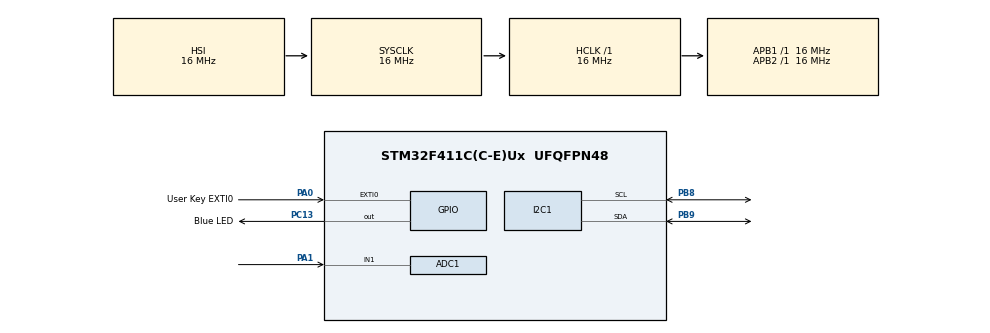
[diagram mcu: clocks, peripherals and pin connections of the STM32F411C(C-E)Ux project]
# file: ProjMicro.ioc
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ADC1.Channel-0\#ChannelRegularConversion=ADC_CHANNEL_1
ADC1.NbrOfConversionFlag=1
ADC1.Rank-0\#ChannelRegularConversion=1
ADC1.SamplingTime-0\#ChannelRegularConversion=ADC_SAMPLETIME_3CYCLES
ADC1.master=1
Mcu.Family=STM32F4
Mcu.Name=STM32F411C(C-E)Ux
Mcu.Package=UFQFPN48
NVIC.ADC_IRQn=true\:0\:0\:false\:false\:true\:true\:true\:true
NVIC.EXTI0_IRQn=true\:0\:0\:false\:false\:true\:true\:true\:true
NVIC.PriorityGroup=NVIC_PRIORITYGROUP_4
NVIC.TIM2_IRQn=true\:0\:0\:false\:false\:true\:true\:true\:true
PA0-WKUP.GPIO_Label=User Key EXTI0
PA0-WKUP.GPIO_PuPd=GPIO_PULLUP
PA0-WKUP.Signal=GPXTI0
PA1.Signal=ADCx_IN1
PA13.Mode=Serial_Wire
PA13.Signal=SYS_JTMS-SWDIO
PA14.Mode=Serial_Wire
PA14.Signal=SYS_JTCK-SWCLK
PB8.Mode=I2C
PB8.Signal=I2C1_SCL
PB9.Mode=I2C
PB9.Signal=I2C1_SDA
PC13-ANTI_TAMP.GPIO_Label=Blue LED
PC13-ANTI_TAMP.PinState=GPIO_PIN_SET
PC13-ANTI_TAMP.Signal=GPIO_Output
PC14-OSC32_IN.Mode=LSE-External-Oscillator
PC14-OSC32_IN.Signal=RCC_OSC32_IN
PC15-OSC32_OUT.Mode=LSE-External-Oscillator
PC15-OSC32_OUT.Signal=RCC_OSC32_OUT
PH0\ -\ OSC_IN.Mode=HSE-External-Oscillator
PH0\ -\ OSC_IN.Signal=RCC_OSC_IN
PH1\ -\ OSC_OUT.Mode=HSE-External-Oscillator
PH1\ -\ OSC_OUT.Signal=RCC_OSC_OUT
ProjectManager.HeapSize=0x200
ProjectManager.StackSize=0x400
ProjectManager.TargetToolchain=CMake
RCC.AHBFreq_Value=16000000
RCC.APB1Freq_Value=16000000
RCC.APB2Freq_Value=16000000
RCC.CortexFreq_Value=16000000
RCC.HSE_VALUE=25000000
RCC.HSI_VALUE=16000000
RCC.SYSCLKFreq_VALUE=16000000
RCC.VCOOutputFreq_Value=192000000
SH.ADCx_IN1.0=ADC1_IN1,IN1
TIM2.AutoReloadPreload=TIM_AUTORELOAD_PRELOAD_ENABLE
TIM2.Period=3999
TIM2.Prescaler=3999
VP_TIM2_VS_ClockSourceINT.Mode=Internal
board=custom

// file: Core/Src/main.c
/* USER CODE BEGIN Header */
/**
  ******************************************************************************
  * @file           : main.c
  * @brief          : Main program body
  ******************************************************************************
  * @attention
  *
  * Copyright (c) 2025 STMicroelectronics.
  * All rights reserved.
  *
  * This software is licensed under terms that can be found in the LICENSE file
  * in the root directory of this software component.
  * If no LICENSE file comes with this software, it is provided AS-IS.
  *
  ******************************************************************************
  */
/* USER CODE END Header */
#include "main.h"

/* USER CODE BEGIN Includes */
#include "stm32f4xx_hal.h"
#include "liquidcrystal_i2c.h"
#include <stdio.h>
#include <stdlib.h>
#include <string.h>

/* USER CODE END Includes */

ADC_HandleTypeDef hadc1;

I2C_HandleTypeDef hi2c1;

TIM_HandleTypeDef htim2;

void SystemClock_Config(void);
static void MX_GPIO_Init(void);
static void MX_I2C1_Init(void);
static void MX_TIM2_Init(void);
static void MX_ADC1_Init(void);

int main(void)
{

  /* MCU Configuration--------------------------------------------------------*/

  /* Reset of all peripherals, Initializes the Flash interface and the Systick. */
  HAL_Init();

  /* Configure the system clock */
  SystemClock_Config();

  /* Initialize all configured peripherals */
  MX_GPIO_Init();
  MX_I2C1_Init();
  MX_TIM2_Init();
  MX_ADC1_Init();
  /* USER CODE BEGIN 2 */
  HAL_TIM_Base_Start_IT(&htim2); //Timer

  HD44780_Init(4);
  HD44780_Clear();
  HD44780_Backlight();

  /* USER CODE END 2 */

  /* Infinite loop */
  while (1)
  {
  HAL_ADC_Start_IT(&hadc1); //ADC
  uint16_t adc1in1;
  float voltage;

  //int inteiro = rand() % 150;  // 0 a 150
  //voltage=inteiro / 100.0f; // Converte para float com 2 casas decimais

  adc1in1 = HAL_ADC_GetValue(&hadc1);
  voltage = (adc1in1*3.3)/4095 -0.2; // Converte o valor do ADC para tensão (0.2V de offset)
  int voltage_int = (int)(voltage * 100); // Converte para inteiro com 2 casas decimais
  char snum[4];
  itoa(voltage_int, snum, 10);
  if (voltage_int<100 && voltage_int>=10) // Verifica se o número é menor que 100
  {
  snum[3] = snum[1]; // Move o segundo dígito para a quarta posição
  snum[2] = snum[0]; // Move o primeiro para a terceira posição
  snum[1] = '.';     // Insere o ponto decimal na segunda posição
  snum[0] = '0';     // Define o primeiro dígito como zero
  }
  else if (voltage_int<10) // Verifica se o número é menor que 10
  {
  snum[3] = snum[0]; // Move o primeiro dígito para a quarta posição
  snum[2] = '0';     // Define o terceiro dígito como zero
  snum[1] = '.';     // Insere o ponto decimal na segunda posição
  snum[0] = '0';     // Define o primeiro dígito como zero
  }
  else
  {
  snum[3] = snum[2]; // Move o terceiro dígito para a quarta posição
  snum[2] = snum[1]; // Move o segundo dígito para a terceira posição
  snum[1] = '.';     // Insere o ponto decimal na segunda posição
  }

  HD44780_Clear();

  if (voltage_int<10){
  HD44780_SetCursor(0,0);
  HD44780_PrintStr("####################");
  HD44780_SetCursor(0,1);
  HD44780_PrintStr("##Inicializando...##");
  HD44780_SetCursor(0,2);
  HD44780_PrintStr("##Insira a bateria##");
  HD44780_SetCursor(0,3);
  HD44780_PrintStr("####################");
  HAL_Delay(2000); //Delay de 2 segundos
  }else{

  HD44780_SetCursor(0,0);
  HD44780_PrintStr("-Medidor de bateria-");
  HD44780_SetCursor(1,1);
  HD44780_PrintStr("Bateria em: ");
  HD44780_SetCursor(14,1);
  HD44780_PrintStr(snum);
  HD44780_SetCursor(18,1);
  HD44780_PrintStr("V ");
  HD44780_SetCursor(0,2);
  HD44780_PrintStr("                    ");
  HD44780_SetCursor(0,3);
  HD44780_PrintStr("                    ");
  HAL_Delay(500); //Delay de 0.5 segundo
  }
  }
}

void SystemClock_Config(void)
{
  RCC_OscInitTypeDef RCC_OscInitStruct = {0};
  RCC_ClkInitTypeDef RCC_ClkInitStruct = {0};

  /** Configure the main internal regulator output voltage
  */
  __HAL_RCC_PWR_CLK_ENABLE();
  __HAL_PWR_VOLTAGESCALING_CONFIG(PWR_REGULATOR_VOLTAGE_SCALE1);

  /** Initializes the RCC Oscillators according to the specified parameters
  * in the RCC_OscInitTypeDef structure.
  */
  RCC_OscInitStruct.OscillatorType = RCC_OSCILLATORTYPE_HSI;
  RCC_OscInitStruct.HSIState = RCC_HSI_ON;
  RCC_OscInitStruct.HSICalibrationValue = RCC_HSICALIBRATION_DEFAULT;
  RCC_OscInitStruct.PLL.PLLState = RCC_PLL_NONE;
  if (HAL_RCC_OscConfig(&RCC_OscInitStruct) != HAL_OK)
  {
    Error_Handler();
  }

  /** Initializes the CPU, AHB and APB buses clocks
  */
  RCC_ClkInitStruct.ClockType = RCC_CLOCKTYPE_HCLK|RCC_CLOCKTYPE_SYSCLK
                              |RCC_CLOCKTYPE_PCLK1|RCC_CLOCKTYPE_PCLK2;
  RCC_ClkInitStruct.SYSCLKSource = RCC_SYSCLKSOURCE_HSI;
  RCC_ClkInitStruct.AHBCLKDivider = RCC_SYSCLK_DIV1;
  RCC_ClkInitStruct.APB1CLKDivider = RCC_HCLK_DIV1;
  RCC_ClkInitStruct.APB2CLKDivider = RCC_HCLK_DIV1;

  if (HAL_RCC_ClockConfig(&RCC_ClkInitStruct, FLASH_LATENCY_0) != HAL_OK)
  {
    Error_Handler();
  }
}

static void MX_ADC1_Init(void)
{

  ADC_ChannelConfTypeDef sConfig = {0};

  /** Configure the global features of the ADC (Clock, Resolution, Data Alignment and number of conversion)
  */
  hadc1.Instance = ADC1;
  hadc1.Init.ClockPrescaler = ADC_CLOCK_SYNC_PCLK_DIV2;
  hadc1.Init.Resolution = ADC_RESOLUTION_12B;
  hadc1.Init.ScanConvMode = DISABLE;
  hadc1.Init.ContinuousConvMode = DISABLE;
  hadc1.Init.DiscontinuousConvMode = DISABLE;
  hadc1.Init.ExternalTrigConvEdge = ADC_EXTERNALTRIGCONVEDGE_NONE;
  hadc1.Init.ExternalTrigConv = ADC_SOFTWARE_START;
  hadc1.Init.DataAlign = ADC_DATAALIGN_RIGHT;
  hadc1.Init.NbrOfConversion = 1;
  hadc1.Init.DMAContinuousRequests = DISABLE;
  hadc1.Init.EOCSelection = ADC_EOC_SINGLE_CONV;
  if (HAL_ADC_Init(&hadc1) != HAL_OK)
  {
    Error_Handler();
  }

  /** Configure for the selected ADC regular channel its corresponding rank in the sequencer and its sample time.
  */
  sConfig.Channel = ADC_CHANNEL_1;
  sConfig.Rank = 1;
  sConfig.SamplingTime = ADC_SAMPLETIME_3CYCLES;
  if (HAL_ADC_ConfigChannel(&hadc1, &sConfig) != HAL_OK)
  {
    Error_Handler();
  }

}

static void MX_I2C1_Init(void)
{

  hi2c1.Instance = I2C1;
  hi2c1.Init.ClockSpeed = 100000;
  hi2c1.Init.DutyCycle = I2C_DUTYCYCLE_2;
  hi2c1.Init.OwnAddress1 = 0;
  hi2c1.Init.AddressingMode = I2C_ADDRESSINGMODE_7BIT;
  hi2c1.Init.DualAddressMode = I2C_DUALADDRESS_DISABLE;
  hi2c1.Init.OwnAddress2 = 0;
  hi2c1.Init.GeneralCallMode = I2C_GENERALCALL_DISABLE;
  hi2c1.Init.NoStretchMode = I2C_NOSTRETCH_DISABLE;
  if (HAL_I2C_Init(&hi2c1) != HAL_OK)
  {
    Error_Handler();
  }

}

static void MX_TIM2_Init(void)
{

  TIM_ClockConfigTypeDef sClockSourceConfig = {0};
  TIM_MasterConfigTypeDef sMasterConfig = {0};

  htim2.Instance = TIM2;
  htim2.Init.Prescaler = 3999;
  htim2.Init.CounterMode = TIM_COUNTERMODE_UP;
  htim2.Init.Period = 3999;
  htim2.Init.ClockDivision = TIM_CLOCKDIVISION_DIV1;
  htim2.Init.AutoReloadPreload = TIM_AUTORELOAD_PRELOAD_ENABLE;
  if (HAL_TIM_Base_Init(&htim2) != HAL_OK)
  {
    Error_Handler();
  }
  sClockSourceConfig.ClockSource = TIM_CLOCKSOURCE_INTERNAL;
  if (HAL_TIM_ConfigClockSource(&htim2, &sClockSourceConfig) != HAL_OK)
  {
    Error_Handler();
  }
  sMasterConfig.MasterOutputTrigger = TIM_TRGO_RESET;
  sMasterConfig.MasterSlaveMode = TIM_MASTERSLAVEMODE_DISABLE;
  if (HAL_TIMEx_MasterConfigSynchronization(&htim2, &sMasterConfig) != HAL_OK)
  {
    Error_Handler();
  }

}

static void MX_GPIO_Init(void)
{
  GPIO_InitTypeDef GPIO_InitStruct = {0};

  /* GPIO Ports Clock Enable */
  __HAL_RCC_GPIOC_CLK_ENABLE();
  __HAL_RCC_GPIOH_CLK_ENABLE();
  __HAL_RCC_GPIOA_CLK_ENABLE();
  __HAL_RCC_GPIOB_CLK_ENABLE();

  /*Configure GPIO pin Output Level */
  HAL_GPIO_WritePin(Blue_LED_GPIO_Port, Blue_LED_Pin, GPIO_PIN_SET);

  /*Configure GPIO pin : Blue_LED_Pin */
  GPIO_InitStruct.Pin = Blue_LED_Pin;
  GPIO_InitStruct.Mode = GPIO_MODE_OUTPUT_PP;
  GPIO_InitStruct.Pull = GPIO_NOPULL;
  GPIO_InitStruct.Speed = GPIO_SPEED_FREQ_LOW;
  HAL_GPIO_Init(Blue_LED_GPIO_Port, &GPIO_InitStruct);

  /*Configure GPIO pin : User_Key_EXTI0_Pin */
  GPIO_InitStruct.Pin = User_Key_EXTI0_Pin;
  GPIO_InitStruct.Mode = GPIO_MODE_IT_RISING;
  GPIO_InitStruct.Pull = GPIO_PULLUP;
  HAL_GPIO_Init(User_Key_EXTI0_GPIO_Port, &GPIO_InitStruct);

  /* EXTI interrupt init*/
  HAL_NVIC_SetPriority(EXTI0_IRQn, 0, 0);
  HAL_NVIC_EnableIRQ(EXTI0_IRQn);

}

void Error_Handler(void)
{
  __disable_irq();
  while (1)
  {
  }
}
